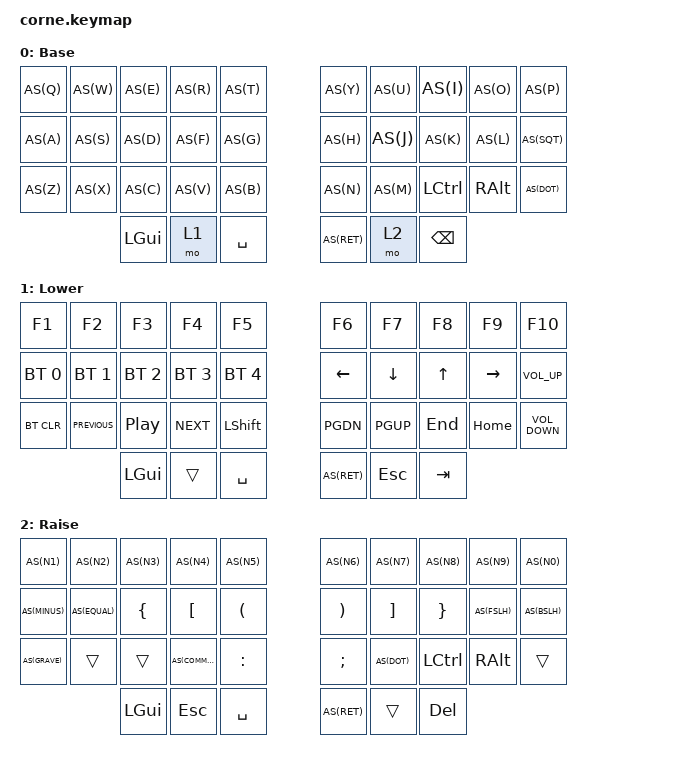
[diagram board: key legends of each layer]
/*
 * Copyright (c) 2020 The ZMK Contributors
 *
 * SPDX-License-Identifier: MIT
 */

#include <behaviors.dtsi>
#include <dt-bindings/zmk/keys.h>
#include <dt-bindings/zmk/bt.h>


#define AS(keycode) &as LS(keycode) keycode

/ {
    chosen {
      zmk,matrix_transform = &five_column_transform;
    };

    behaviors {
        as: auto_shift {
            compatible = "zmk,behavior-hold-tap";
            #binding-cells = <2>;
            tapping_term_ms = <400>;
            quick_tap_ms = <0>;
            flavor = "tap-preferred";
            bindings = <&kp>, <&kp>;
        };
    };
        keymap {
                compatible = "zmk,keymap";

                default_layer {
// -----------------------------------------------------------------------------------------
// |  Q  |  W  |  E  |  R  |  T  |     |  Y  |  U   |  I   |  O   | P |
// |  A  |  S  |  D  |  F  |  G  |     |  H  |  J   |  K   |  L   | ' | 
// |  Z  |  X  |  C  |  V  |  B  |     |  N  |  M   | CTRL | META | . |
//             | GUI | LWR | SPC |     | ENT | RSE  | BSPC |
                        display-name = "Base";
                        bindings = <
   AS(Q) AS(W) AS(E) AS(R) AS(T)     AS(Y)   AS(U)  AS(I)     AS(O)     AS(P)
   AS(A) AS(S) AS(D) AS(F) AS(G)     AS(H)   AS(J)  AS(K)     AS(L)     AS(SQT)
   AS(Z) AS(X) AS(C) AS(V) AS(B)     AS(N)   AS(M)  &kp LCTL  &kp RALT  AS(DOT)
        &kp LGUI &mo 1 &kp SPACE     AS(RET) &mo 2  &kp BSPC
                        >;
                };

                lower_layer {
// -----------------------------------------------------------------------------------------
// | F1    |  F2 |  F3 |  F4 |  F5 |     |  F6 |  F7 |  F8 |  F9 | F10 |
// | BT1   | BT2 | BT3 | BT4 | BT5 |     | LFT | DWN |  UP | RGT |   VOL+  |
// | BTCLR |  Prev   |  P/P   |  Next   | LS  |     | PGUP| PGDN| END  |  HOME   |  VOL-   |
//               | GUI |     | SPC |     | ENT | ESC | TAB |
                        display-name = "Lower";
                        bindings = <
   &kp F1       &kp F2       &kp F3       &kp F4       &kp F5           &kp F6    &kp F7    &kp F8  &kp F9  &kp F10
   &bt BT_SEL 0 &bt BT_SEL 1 &bt BT_SEL 2 &bt BT_SEL 3 &bt BT_SEL 4     &kp LEFT  &kp DOWN  &kp UP  &kp RIGHT &kp C_VOLUME_UP 
   &bt BT_CLR   &kp C_PREVIOUS       &kp C_PLAY_PAUSE       &kp C_NEXT       &kp LEFT_SHIFT           &kp PGDN  &kp PGUP  &kp END  &kp HOME    &kp C_VOLUME_DOWN 
                             &kp LGUI     &trans       &kp SPACE        AS(RET)   &kp ESC   &kp TAB
                        >;
                };

                raise_layer {
// -----------------------------------------------------------------------------------------
// | 1! |  2@ |  3# |  4$ |  5% |     |  6^ |  7& |  8* |  9(  |  0)  |
// | -_ |  =+ |  {  |  [  |  (  |     |  )  |  ]  |  }  |  /?  |  \|  |
// | `~ |     |     |  ,< |  :  |     |  ;  |  .> | CTRL| META |      |
//            | GUI | ESC | SPC |     | ENT |     | DEL |
                        display-name = "Raise";
                        bindings = <

   AS(N1)    AS(N2)    AS(N3)    AS(N4)    AS(N5)        AS(N6)    AS(N7)    AS(N8)    AS(N9)   AS(N0)
   AS(MINUS) AS(EQUAL) &kp LBRC  &kp LBKT  &kp LPAR      &kp RPAR  &kp RBKT  &kp RBRC  AS(FSLH) AS(BSLH)
   AS(GRAVE) &trans    &trans    AS(COMMA) &kp COLON     &kp SEMI  AS(DOT)   &kp LCTRL &kp RALT &trans
                       &kp LGUI  &kp ESC   &kp SPACE     AS(RET)   &trans    &kp DEL
                        >;
                };
        };
};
